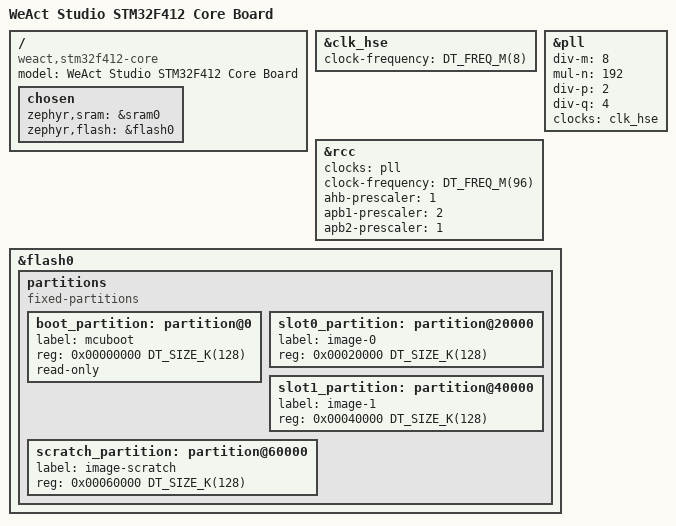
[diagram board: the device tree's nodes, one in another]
/* SPDX-License-Identifier: Apache-2.0 */

/dts-v1/;
#include <st/f4/stm32f412Xe.dtsi>
#include <st/f4/stm32f412r(e-g)tx-pinctrl.dtsi>
#include <zephyr/dt-bindings/clock/stm32f410_clock.h>

/ {
	model = "WeAct Studio STM32F412 Core Board";
	compatible = "weact,stm32f412-core", "st,stm32f412";

	chosen {
		zephyr,sram = &sram0;
		zephyr,flash = &flash0;
	};
};

&clk_hse {
	clock-frequency = <DT_FREQ_M(8)>;
	status = "okay";
};

&pll {
	div-m = <8>;
	mul-n = <192>;
	div-p = <2>;
	div-q = <4>;
	clocks = <&clk_hse>;
	status = "okay";
};

&rcc {
	clocks = <&pll>;
	clock-frequency = <DT_FREQ_M(96)>;
	ahb-prescaler = <1>;
	apb1-prescaler = <2>;
	apb2-prescaler = <1>;
};

&flash0 {
	partitions {
		compatible = "fixed-partitions";
		#address-cells = <1>;
		#size-cells = <1>;

		boot_partition: partition@0 {
			label = "mcuboot";
			reg = <0x00000000 DT_SIZE_K(128)>;
			read-only;
		};

		slot0_partition: partition@20000 {
			label = "image-0";
			reg = <0x00020000 DT_SIZE_K(128)>;
		};

		slot1_partition: partition@40000 {
			label = "image-1";
			reg = <0x00040000 DT_SIZE_K(128)>;
		};

		scratch_partition: partition@60000 {
			label = "image-scratch";
			reg = <0x00060000 DT_SIZE_K(128)>;
		};
	};
};

